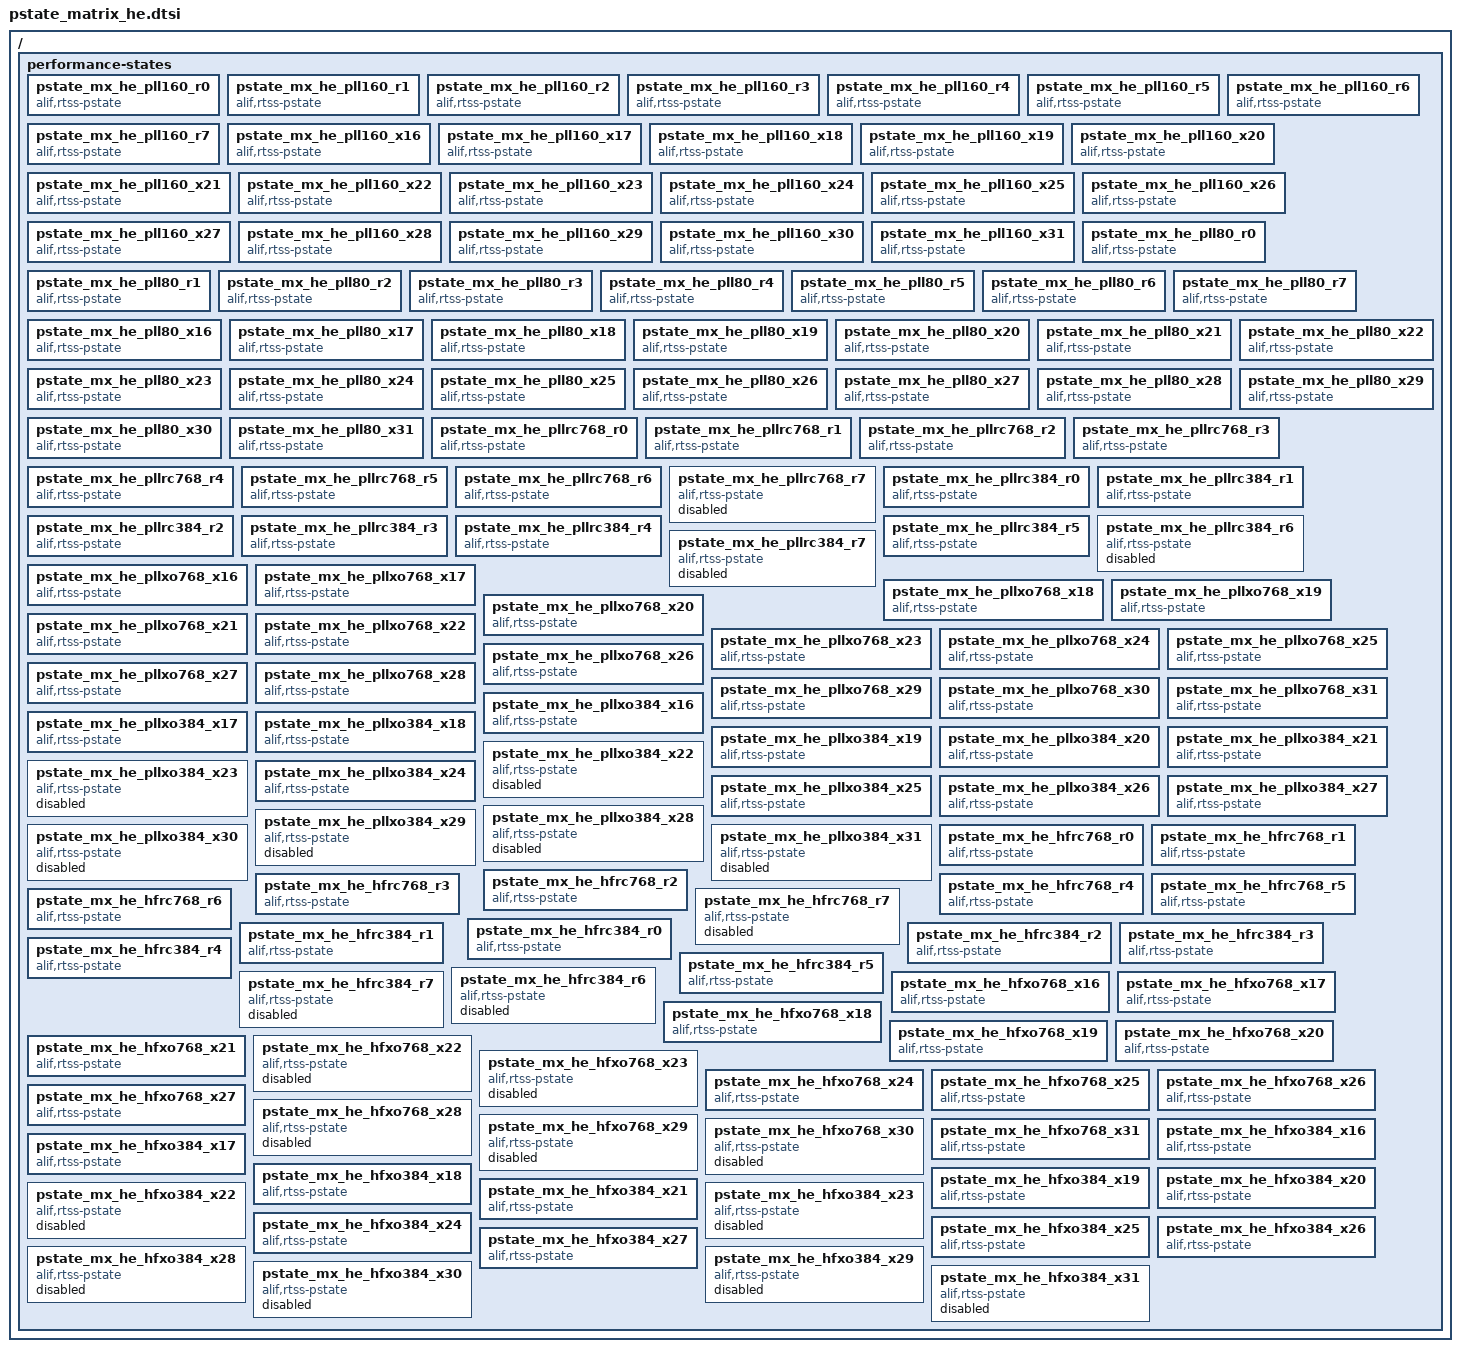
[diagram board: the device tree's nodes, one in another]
/* SPDX-FileCopyrightText: Copyright Analog Devices, Inc. */
/* SPDX-License-Identifier: Apache-2.0 */
/* Generated by scripts/regen_pstate_matrix.py */
/* HE matrix for E7/E8 (also E3/E4): PLL 160 and 80 MHz,
 * PLL x HFRC/HFXO cpu-clk-freq, HFRC src, and HFXO src.
 * E1C/B1 use pstate_matrix_he_e1c_b1.dtsi (160/80/120/60 + osc).
 */
#include <dt-bindings/misc/alif_aipm_common.h>

/ {
	performance-states {
		pstate_mx_he_pll160_r0: pstate_mx_he_pll160_r0 {
			compatible = "alif,rtss-pstate";
			load-threshold = <0>;
			cpu-clk-freq = <ALIF_CLOCK_FREQ_160MHZ>;
			clk-src = "pll";
			scaled-clk-freq = <ALIF_SCALED_FREQ_RC_ACTIVE_76_8_MHZ>;
			status = "okay";
		};
		pstate_mx_he_pll160_r1: pstate_mx_he_pll160_r1 {
			compatible = "alif,rtss-pstate";
			load-threshold = <0>;
			cpu-clk-freq = <ALIF_CLOCK_FREQ_160MHZ>;
			clk-src = "pll";
			scaled-clk-freq = <ALIF_SCALED_FREQ_RC_ACTIVE_38_4_MHZ>;
			status = "okay";
		};
		pstate_mx_he_pll160_r2: pstate_mx_he_pll160_r2 {
			compatible = "alif,rtss-pstate";
			load-threshold = <0>;
			cpu-clk-freq = <ALIF_CLOCK_FREQ_160MHZ>;
			clk-src = "pll";
			scaled-clk-freq = <ALIF_SCALED_FREQ_RC_ACTIVE_19_2_MHZ>;
			status = "okay";
		};
		pstate_mx_he_pll160_r3: pstate_mx_he_pll160_r3 {
			compatible = "alif,rtss-pstate";
			load-threshold = <0>;
			cpu-clk-freq = <ALIF_CLOCK_FREQ_160MHZ>;
			clk-src = "pll";
			scaled-clk-freq = <ALIF_SCALED_FREQ_RC_ACTIVE_9_6_MHZ>;
			status = "okay";
		};
		pstate_mx_he_pll160_r4: pstate_mx_he_pll160_r4 {
			compatible = "alif,rtss-pstate";
			load-threshold = <0>;
			cpu-clk-freq = <ALIF_CLOCK_FREQ_160MHZ>;
			clk-src = "pll";
			scaled-clk-freq = <ALIF_SCALED_FREQ_RC_ACTIVE_4_8_MHZ>;
			status = "okay";
		};
		pstate_mx_he_pll160_r5: pstate_mx_he_pll160_r5 {
			compatible = "alif,rtss-pstate";
			load-threshold = <0>;
			cpu-clk-freq = <ALIF_CLOCK_FREQ_160MHZ>;
			clk-src = "pll";
			scaled-clk-freq = <ALIF_SCALED_FREQ_RC_ACTIVE_2_4_MHZ>;
			status = "okay";
		};
		pstate_mx_he_pll160_r6: pstate_mx_he_pll160_r6 {
			compatible = "alif,rtss-pstate";
			load-threshold = <0>;
			cpu-clk-freq = <ALIF_CLOCK_FREQ_160MHZ>;
			clk-src = "pll";
			scaled-clk-freq = <ALIF_SCALED_FREQ_RC_ACTIVE_1_2_MHZ>;
			status = "okay";
		};
		pstate_mx_he_pll160_r7: pstate_mx_he_pll160_r7 {
			compatible = "alif,rtss-pstate";
			load-threshold = <0>;
			cpu-clk-freq = <ALIF_CLOCK_FREQ_160MHZ>;
			clk-src = "pll";
			scaled-clk-freq = <ALIF_SCALED_FREQ_RC_ACTIVE_0_6_MHZ>;
			status = "okay";
		};
		pstate_mx_he_pll160_x16: pstate_mx_he_pll160_x16 {
			compatible = "alif,rtss-pstate";
			load-threshold = <0>;
			cpu-clk-freq = <ALIF_CLOCK_FREQ_160MHZ>;
			clk-src = "pll";
			scaled-clk-freq = <ALIF_SCALED_FREQ_XO_LOW_DIV_38_4_MHZ>;
			status = "okay";
		};
		pstate_mx_he_pll160_x17: pstate_mx_he_pll160_x17 {
			compatible = "alif,rtss-pstate";
			load-threshold = <0>;
			cpu-clk-freq = <ALIF_CLOCK_FREQ_160MHZ>;
			clk-src = "pll";
			scaled-clk-freq = <ALIF_SCALED_FREQ_XO_LOW_DIV_19_2_MHZ>;
			status = "okay";
		};
		pstate_mx_he_pll160_x18: pstate_mx_he_pll160_x18 {
			compatible = "alif,rtss-pstate";
			load-threshold = <0>;
			cpu-clk-freq = <ALIF_CLOCK_FREQ_160MHZ>;
			clk-src = "pll";
			scaled-clk-freq = <ALIF_SCALED_FREQ_XO_LOW_DIV_9_6_MHZ>;
			status = "okay";
		};
		pstate_mx_he_pll160_x19: pstate_mx_he_pll160_x19 {
			compatible = "alif,rtss-pstate";
			load-threshold = <0>;
			cpu-clk-freq = <ALIF_CLOCK_FREQ_160MHZ>;
			clk-src = "pll";
			scaled-clk-freq = <ALIF_SCALED_FREQ_XO_LOW_DIV_4_8_MHZ>;
			status = "okay";
		};
		pstate_mx_he_pll160_x20: pstate_mx_he_pll160_x20 {
			compatible = "alif,rtss-pstate";
			load-threshold = <0>;
			cpu-clk-freq = <ALIF_CLOCK_FREQ_160MHZ>;
			clk-src = "pll";
			scaled-clk-freq = <ALIF_SCALED_FREQ_XO_LOW_DIV_2_4_MHZ>;
			status = "okay";
		};
		pstate_mx_he_pll160_x21: pstate_mx_he_pll160_x21 {
			compatible = "alif,rtss-pstate";
			load-threshold = <0>;
			cpu-clk-freq = <ALIF_CLOCK_FREQ_160MHZ>;
			clk-src = "pll";
			scaled-clk-freq = <ALIF_SCALED_FREQ_XO_LOW_DIV_1_2_MHZ>;
			status = "okay";
		};
		pstate_mx_he_pll160_x22: pstate_mx_he_pll160_x22 {
			compatible = "alif,rtss-pstate";
			load-threshold = <0>;
			cpu-clk-freq = <ALIF_CLOCK_FREQ_160MHZ>;
			clk-src = "pll";
			scaled-clk-freq = <ALIF_SCALED_FREQ_XO_LOW_DIV_0_6_MHZ>;
			status = "okay";
		};
		pstate_mx_he_pll160_x23: pstate_mx_he_pll160_x23 {
			compatible = "alif,rtss-pstate";
			load-threshold = <0>;
			cpu-clk-freq = <ALIF_CLOCK_FREQ_160MHZ>;
			clk-src = "pll";
			scaled-clk-freq = <ALIF_SCALED_FREQ_XO_LOW_DIV_0_3_MHZ>;
			status = "okay";
		};
		pstate_mx_he_pll160_x24: pstate_mx_he_pll160_x24 {
			compatible = "alif,rtss-pstate";
			load-threshold = <0>;
			cpu-clk-freq = <ALIF_CLOCK_FREQ_160MHZ>;
			clk-src = "pll";
			scaled-clk-freq = <ALIF_SCALED_FREQ_XO_HIGH_DIV_38_4_MHZ>;
			status = "okay";
		};
		pstate_mx_he_pll160_x25: pstate_mx_he_pll160_x25 {
			compatible = "alif,rtss-pstate";
			load-threshold = <0>;
			cpu-clk-freq = <ALIF_CLOCK_FREQ_160MHZ>;
			clk-src = "pll";
			scaled-clk-freq = <ALIF_SCALED_FREQ_XO_HIGH_DIV_19_2_MHZ>;
			status = "okay";
		};
		pstate_mx_he_pll160_x26: pstate_mx_he_pll160_x26 {
			compatible = "alif,rtss-pstate";
			load-threshold = <0>;
			cpu-clk-freq = <ALIF_CLOCK_FREQ_160MHZ>;
			clk-src = "pll";
			scaled-clk-freq = <ALIF_SCALED_FREQ_XO_HIGH_DIV_9_6_MHZ>;
			status = "okay";
		};
		pstate_mx_he_pll160_x27: pstate_mx_he_pll160_x27 {
			compatible = "alif,rtss-pstate";
			load-threshold = <0>;
			cpu-clk-freq = <ALIF_CLOCK_FREQ_160MHZ>;
			clk-src = "pll";
			scaled-clk-freq = <ALIF_SCALED_FREQ_XO_HIGH_DIV_2_4_MHZ>;
			status = "okay";
		};
		pstate_mx_he_pll160_x28: pstate_mx_he_pll160_x28 {
			compatible = "alif,rtss-pstate";
			load-threshold = <0>;
			cpu-clk-freq = <ALIF_CLOCK_FREQ_160MHZ>;
			clk-src = "pll";
			scaled-clk-freq = <ALIF_SCALED_FREQ_XO_HIGH_DIV_0_6_MHZ>;
			status = "okay";
		};
		pstate_mx_he_pll160_x29: pstate_mx_he_pll160_x29 {
			compatible = "alif,rtss-pstate";
			load-threshold = <0>;
			cpu-clk-freq = <ALIF_CLOCK_FREQ_160MHZ>;
			clk-src = "pll";
			scaled-clk-freq = <ALIF_SCALED_FREQ_XO_HIGH_DIV_0_3_MHZ>;
			status = "okay";
		};
		pstate_mx_he_pll160_x30: pstate_mx_he_pll160_x30 {
			compatible = "alif,rtss-pstate";
			load-threshold = <0>;
			cpu-clk-freq = <ALIF_CLOCK_FREQ_160MHZ>;
			clk-src = "pll";
			scaled-clk-freq = <ALIF_SCALED_FREQ_XO_HIGH_DIV_0_15_MHZ>;
			status = "okay";
		};
		pstate_mx_he_pll160_x31: pstate_mx_he_pll160_x31 {
			compatible = "alif,rtss-pstate";
			load-threshold = <0>;
			cpu-clk-freq = <ALIF_CLOCK_FREQ_160MHZ>;
			clk-src = "pll";
			scaled-clk-freq = <ALIF_SCALED_FREQ_XO_HIGH_DIV_0_0375_MHZ>;
			status = "okay";
		};
		pstate_mx_he_pll80_r0: pstate_mx_he_pll80_r0 {
			compatible = "alif,rtss-pstate";
			load-threshold = <0>;
			cpu-clk-freq = <ALIF_CLOCK_FREQ_80MHZ>;
			clk-src = "pll";
			scaled-clk-freq = <ALIF_SCALED_FREQ_RC_ACTIVE_76_8_MHZ>;
			status = "okay";
		};
		pstate_mx_he_pll80_r1: pstate_mx_he_pll80_r1 {
			compatible = "alif,rtss-pstate";
			load-threshold = <0>;
			cpu-clk-freq = <ALIF_CLOCK_FREQ_80MHZ>;
			clk-src = "pll";
			scaled-clk-freq = <ALIF_SCALED_FREQ_RC_ACTIVE_38_4_MHZ>;
			status = "okay";
		};
		pstate_mx_he_pll80_r2: pstate_mx_he_pll80_r2 {
			compatible = "alif,rtss-pstate";
			load-threshold = <0>;
			cpu-clk-freq = <ALIF_CLOCK_FREQ_80MHZ>;
			clk-src = "pll";
			scaled-clk-freq = <ALIF_SCALED_FREQ_RC_ACTIVE_19_2_MHZ>;
			status = "okay";
		};
		pstate_mx_he_pll80_r3: pstate_mx_he_pll80_r3 {
			compatible = "alif,rtss-pstate";
			load-threshold = <0>;
			cpu-clk-freq = <ALIF_CLOCK_FREQ_80MHZ>;
			clk-src = "pll";
			scaled-clk-freq = <ALIF_SCALED_FREQ_RC_ACTIVE_9_6_MHZ>;
			status = "okay";
		};
		pstate_mx_he_pll80_r4: pstate_mx_he_pll80_r4 {
			compatible = "alif,rtss-pstate";
			load-threshold = <0>;
			cpu-clk-freq = <ALIF_CLOCK_FREQ_80MHZ>;
			clk-src = "pll";
			scaled-clk-freq = <ALIF_SCALED_FREQ_RC_ACTIVE_4_8_MHZ>;
			status = "okay";
		};
		pstate_mx_he_pll80_r5: pstate_mx_he_pll80_r5 {
			compatible = "alif,rtss-pstate";
			load-threshold = <0>;
			cpu-clk-freq = <ALIF_CLOCK_FREQ_80MHZ>;
			clk-src = "pll";
			scaled-clk-freq = <ALIF_SCALED_FREQ_RC_ACTIVE_2_4_MHZ>;
			status = "okay";
		};
		pstate_mx_he_pll80_r6: pstate_mx_he_pll80_r6 {
			compatible = "alif,rtss-pstate";
			load-threshold = <0>;
			cpu-clk-freq = <ALIF_CLOCK_FREQ_80MHZ>;
			clk-src = "pll";
			scaled-clk-freq = <ALIF_SCALED_FREQ_RC_ACTIVE_1_2_MHZ>;
			status = "okay";
		};
		pstate_mx_he_pll80_r7: pstate_mx_he_pll80_r7 {
			compatible = "alif,rtss-pstate";
			load-threshold = <0>;
			cpu-clk-freq = <ALIF_CLOCK_FREQ_80MHZ>;
			clk-src = "pll";
			scaled-clk-freq = <ALIF_SCALED_FREQ_RC_ACTIVE_0_6_MHZ>;
			status = "okay";
		};
		pstate_mx_he_pll80_x16: pstate_mx_he_pll80_x16 {
			compatible = "alif,rtss-pstate";
			load-threshold = <0>;
			cpu-clk-freq = <ALIF_CLOCK_FREQ_80MHZ>;
			clk-src = "pll";
			scaled-clk-freq = <ALIF_SCALED_FREQ_XO_LOW_DIV_38_4_MHZ>;
			status = "okay";
		};
		pstate_mx_he_pll80_x17: pstate_mx_he_pll80_x17 {
			compatible = "alif,rtss-pstate";
			load-threshold = <0>;
			cpu-clk-freq = <ALIF_CLOCK_FREQ_80MHZ>;
			clk-src = "pll";
			scaled-clk-freq = <ALIF_SCALED_FREQ_XO_LOW_DIV_19_2_MHZ>;
			status = "okay";
		};
		pstate_mx_he_pll80_x18: pstate_mx_he_pll80_x18 {
			compatible = "alif,rtss-pstate";
			load-threshold = <0>;
			cpu-clk-freq = <ALIF_CLOCK_FREQ_80MHZ>;
			clk-src = "pll";
			scaled-clk-freq = <ALIF_SCALED_FREQ_XO_LOW_DIV_9_6_MHZ>;
			status = "okay";
		};
		pstate_mx_he_pll80_x19: pstate_mx_he_pll80_x19 {
			compatible = "alif,rtss-pstate";
			load-threshold = <0>;
			cpu-clk-freq = <ALIF_CLOCK_FREQ_80MHZ>;
			clk-src = "pll";
			scaled-clk-freq = <ALIF_SCALED_FREQ_XO_LOW_DIV_4_8_MHZ>;
			status = "okay";
		};
		pstate_mx_he_pll80_x20: pstate_mx_he_pll80_x20 {
			compatible = "alif,rtss-pstate";
			load-threshold = <0>;
			cpu-clk-freq = <ALIF_CLOCK_FREQ_80MHZ>;
			clk-src = "pll";
			scaled-clk-freq = <ALIF_SCALED_FREQ_XO_LOW_DIV_2_4_MHZ>;
			status = "okay";
		};
		pstate_mx_he_pll80_x21: pstate_mx_he_pll80_x21 {
			compatible = "alif,rtss-pstate";
			load-threshold = <0>;
			cpu-clk-freq = <ALIF_CLOCK_FREQ_80MHZ>;
			clk-src = "pll";
			scaled-clk-freq = <ALIF_SCALED_FREQ_XO_LOW_DIV_1_2_MHZ>;
			status = "okay";
		};
		pstate_mx_he_pll80_x22: pstate_mx_he_pll80_x22 {
			compatible = "alif,rtss-pstate";
			load-threshold = <0>;
			cpu-clk-freq = <ALIF_CLOCK_FREQ_80MHZ>;
			clk-src = "pll";
			scaled-clk-freq = <ALIF_SCALED_FREQ_XO_LOW_DIV_0_6_MHZ>;
			status = "okay";
		};
		pstate_mx_he_pll80_x23: pstate_mx_he_pll80_x23 {
			compatible = "alif,rtss-pstate";
			load-threshold = <0>;
			cpu-clk-freq = <ALIF_CLOCK_FREQ_80MHZ>;
			clk-src = "pll";
			scaled-clk-freq = <ALIF_SCALED_FREQ_XO_LOW_DIV_0_3_MHZ>;
			status = "okay";
		};
		pstate_mx_he_pll80_x24: pstate_mx_he_pll80_x24 {
			compatible = "alif,rtss-pstate";
			load-threshold = <0>;
			cpu-clk-freq = <ALIF_CLOCK_FREQ_80MHZ>;
			clk-src = "pll";
			scaled-clk-freq = <ALIF_SCALED_FREQ_XO_HIGH_DIV_38_4_MHZ>;
			status = "okay";
		};
		pstate_mx_he_pll80_x25: pstate_mx_he_pll80_x25 {
			compatible = "alif,rtss-pstate";
			load-threshold = <0>;
			cpu-clk-freq = <ALIF_CLOCK_FREQ_80MHZ>;
			clk-src = "pll";
			scaled-clk-freq = <ALIF_SCALED_FREQ_XO_HIGH_DIV_19_2_MHZ>;
			status = "okay";
		};
		pstate_mx_he_pll80_x26: pstate_mx_he_pll80_x26 {
			compatible = "alif,rtss-pstate";
			load-threshold = <0>;
			cpu-clk-freq = <ALIF_CLOCK_FREQ_80MHZ>;
			clk-src = "pll";
			scaled-clk-freq = <ALIF_SCALED_FREQ_XO_HIGH_DIV_9_6_MHZ>;
			status = "okay";
		};
		pstate_mx_he_pll80_x27: pstate_mx_he_pll80_x27 {
			compatible = "alif,rtss-pstate";
			load-threshold = <0>;
			cpu-clk-freq = <ALIF_CLOCK_FREQ_80MHZ>;
			clk-src = "pll";
			scaled-clk-freq = <ALIF_SCALED_FREQ_XO_HIGH_DIV_2_4_MHZ>;
			status = "okay";
		};
		pstate_mx_he_pll80_x28: pstate_mx_he_pll80_x28 {
			compatible = "alif,rtss-pstate";
			load-threshold = <0>;
			cpu-clk-freq = <ALIF_CLOCK_FREQ_80MHZ>;
			clk-src = "pll";
			scaled-clk-freq = <ALIF_SCALED_FREQ_XO_HIGH_DIV_0_6_MHZ>;
			status = "okay";
		};
		pstate_mx_he_pll80_x29: pstate_mx_he_pll80_x29 {
			compatible = "alif,rtss-pstate";
			load-threshold = <0>;
			cpu-clk-freq = <ALIF_CLOCK_FREQ_80MHZ>;
			clk-src = "pll";
			scaled-clk-freq = <ALIF_SCALED_FREQ_XO_HIGH_DIV_0_3_MHZ>;
			status = "okay";
		};
		pstate_mx_he_pll80_x30: pstate_mx_he_pll80_x30 {
			compatible = "alif,rtss-pstate";
			load-threshold = <0>;
			cpu-clk-freq = <ALIF_CLOCK_FREQ_80MHZ>;
			clk-src = "pll";
			scaled-clk-freq = <ALIF_SCALED_FREQ_XO_HIGH_DIV_0_15_MHZ>;
			status = "okay";
		};
		pstate_mx_he_pll80_x31: pstate_mx_he_pll80_x31 {
			compatible = "alif,rtss-pstate";
			load-threshold = <0>;
			cpu-clk-freq = <ALIF_CLOCK_FREQ_80MHZ>;
			clk-src = "pll";
			scaled-clk-freq = <ALIF_SCALED_FREQ_XO_HIGH_DIV_0_0375_MHZ>;
			status = "okay";
		};
		pstate_mx_he_pllrc768_r0: pstate_mx_he_pllrc768_r0 {
			compatible = "alif,rtss-pstate";
			load-threshold = <0>;
			cpu-clk-freq = <ALIF_CLOCK_FREQ_76_8_RC_MHZ>;
			clk-src = "pll";
			scaled-clk-freq = <ALIF_SCALED_FREQ_RC_ACTIVE_76_8_MHZ>;
			status = "okay";
		};
		pstate_mx_he_pllrc768_r1: pstate_mx_he_pllrc768_r1 {
			compatible = "alif,rtss-pstate";
			load-threshold = <0>;
			cpu-clk-freq = <ALIF_CLOCK_FREQ_76_8_RC_MHZ>;
			clk-src = "pll";
			scaled-clk-freq = <ALIF_SCALED_FREQ_RC_ACTIVE_38_4_MHZ>;
			status = "okay";
		};
		pstate_mx_he_pllrc768_r2: pstate_mx_he_pllrc768_r2 {
			compatible = "alif,rtss-pstate";
			load-threshold = <0>;
			cpu-clk-freq = <ALIF_CLOCK_FREQ_76_8_RC_MHZ>;
			clk-src = "pll";
			scaled-clk-freq = <ALIF_SCALED_FREQ_RC_ACTIVE_19_2_MHZ>;
			status = "okay";
		};
		pstate_mx_he_pllrc768_r3: pstate_mx_he_pllrc768_r3 {
			compatible = "alif,rtss-pstate";
			load-threshold = <0>;
			cpu-clk-freq = <ALIF_CLOCK_FREQ_76_8_RC_MHZ>;
			clk-src = "pll";
			scaled-clk-freq = <ALIF_SCALED_FREQ_RC_ACTIVE_9_6_MHZ>;
			status = "okay";
		};
		pstate_mx_he_pllrc768_r4: pstate_mx_he_pllrc768_r4 {
			compatible = "alif,rtss-pstate";
			load-threshold = <0>;
			cpu-clk-freq = <ALIF_CLOCK_FREQ_76_8_RC_MHZ>;
			clk-src = "pll";
			scaled-clk-freq = <ALIF_SCALED_FREQ_RC_ACTIVE_4_8_MHZ>;
			status = "okay";
		};
		pstate_mx_he_pllrc768_r5: pstate_mx_he_pllrc768_r5 {
			compatible = "alif,rtss-pstate";
			load-threshold = <0>;
			cpu-clk-freq = <ALIF_CLOCK_FREQ_76_8_RC_MHZ>;
			clk-src = "pll";
			scaled-clk-freq = <ALIF_SCALED_FREQ_RC_ACTIVE_2_4_MHZ>;
			status = "okay";
		};
		pstate_mx_he_pllrc768_r6: pstate_mx_he_pllrc768_r6 {
			compatible = "alif,rtss-pstate";
			load-threshold = <0>;
			cpu-clk-freq = <ALIF_CLOCK_FREQ_76_8_RC_MHZ>;
			clk-src = "pll";
			scaled-clk-freq = <ALIF_SCALED_FREQ_RC_ACTIVE_1_2_MHZ>;
			status = "okay";
		};
		/* Not in the default walk. Set status okay to verify this scaled frequency. */
		pstate_mx_he_pllrc768_r7: pstate_mx_he_pllrc768_r7 {
			compatible = "alif,rtss-pstate";
			load-threshold = <0>;
			cpu-clk-freq = <ALIF_CLOCK_FREQ_76_8_RC_MHZ>;
			clk-src = "pll";
			scaled-clk-freq = <ALIF_SCALED_FREQ_RC_ACTIVE_0_6_MHZ>;
			status = "disabled";
		};
		pstate_mx_he_pllrc384_r0: pstate_mx_he_pllrc384_r0 {
			compatible = "alif,rtss-pstate";
			load-threshold = <0>;
			cpu-clk-freq = <ALIF_CLOCK_FREQ_38_4_RC_MHZ>;
			clk-src = "pll";
			scaled-clk-freq = <ALIF_SCALED_FREQ_RC_ACTIVE_76_8_MHZ>;
			status = "okay";
		};
		pstate_mx_he_pllrc384_r1: pstate_mx_he_pllrc384_r1 {
			compatible = "alif,rtss-pstate";
			load-threshold = <0>;
			cpu-clk-freq = <ALIF_CLOCK_FREQ_38_4_RC_MHZ>;
			clk-src = "pll";
			scaled-clk-freq = <ALIF_SCALED_FREQ_RC_ACTIVE_38_4_MHZ>;
			status = "okay";
		};
		pstate_mx_he_pllrc384_r2: pstate_mx_he_pllrc384_r2 {
			compatible = "alif,rtss-pstate";
			load-threshold = <0>;
			cpu-clk-freq = <ALIF_CLOCK_FREQ_38_4_RC_MHZ>;
			clk-src = "pll";
			scaled-clk-freq = <ALIF_SCALED_FREQ_RC_ACTIVE_19_2_MHZ>;
			status = "okay";
		};
		pstate_mx_he_pllrc384_r3: pstate_mx_he_pllrc384_r3 {
			compatible = "alif,rtss-pstate";
			load-threshold = <0>;
			cpu-clk-freq = <ALIF_CLOCK_FREQ_38_4_RC_MHZ>;
			clk-src = "pll";
			scaled-clk-freq = <ALIF_SCALED_FREQ_RC_ACTIVE_9_6_MHZ>;
			status = "okay";
		};
		pstate_mx_he_pllrc384_r4: pstate_mx_he_pllrc384_r4 {
			compatible = "alif,rtss-pstate";
			load-threshold = <0>;
			cpu-clk-freq = <ALIF_CLOCK_FREQ_38_4_RC_MHZ>;
			clk-src = "pll";
			scaled-clk-freq = <ALIF_SCALED_FREQ_RC_ACTIVE_4_8_MHZ>;
			status = "okay";
		};
		pstate_mx_he_pllrc384_r5: pstate_mx_he_pllrc384_r5 {
			compatible = "alif,rtss-pstate";
			load-threshold = <0>;
			cpu-clk-freq = <ALIF_CLOCK_FREQ_38_4_RC_MHZ>;
			clk-src = "pll";
			scaled-clk-freq = <ALIF_SCALED_FREQ_RC_ACTIVE_2_4_MHZ>;
			status = "okay";
		};

		/* Not in the default walk. Set status okay to verify this scaled frequency. */
		pstate_mx_he_pllrc384_r6: pstate_mx_he_pllrc384_r6 {
			compatible = "alif,rtss-pstate";
			load-threshold = <0>;
			cpu-clk-freq = <ALIF_CLOCK_FREQ_38_4_RC_MHZ>;
			clk-src = "pll";
			scaled-clk-freq = <ALIF_SCALED_FREQ_RC_ACTIVE_1_2_MHZ>;
			status = "disabled";
		};

		/* Not in the default walk. Set status okay to verify this scaled frequency. */
		pstate_mx_he_pllrc384_r7: pstate_mx_he_pllrc384_r7 {
			compatible = "alif,rtss-pstate";
			load-threshold = <0>;
			cpu-clk-freq = <ALIF_CLOCK_FREQ_38_4_RC_MHZ>;
			clk-src = "pll";
			scaled-clk-freq = <ALIF_SCALED_FREQ_RC_ACTIVE_0_6_MHZ>;
			status = "disabled";
		};
		pstate_mx_he_pllxo768_x16: pstate_mx_he_pllxo768_x16 {
			compatible = "alif,rtss-pstate";
			load-threshold = <0>;
			cpu-clk-freq = <ALIF_CLOCK_FREQ_76_8_XO_MHZ>;
			clk-src = "pll";
			scaled-clk-freq = <ALIF_SCALED_FREQ_XO_LOW_DIV_38_4_MHZ>;
			status = "okay";
		};
		pstate_mx_he_pllxo768_x17: pstate_mx_he_pllxo768_x17 {
			compatible = "alif,rtss-pstate";
			load-threshold = <0>;
			cpu-clk-freq = <ALIF_CLOCK_FREQ_76_8_XO_MHZ>;
			clk-src = "pll";
			scaled-clk-freq = <ALIF_SCALED_FREQ_XO_LOW_DIV_19_2_MHZ>;
			status = "okay";
		};
		pstate_mx_he_pllxo768_x18: pstate_mx_he_pllxo768_x18 {
			compatible = "alif,rtss-pstate";
			load-threshold = <0>;
			cpu-clk-freq = <ALIF_CLOCK_FREQ_76_8_XO_MHZ>;
			clk-src = "pll";
			scaled-clk-freq = <ALIF_SCALED_FREQ_XO_LOW_DIV_9_6_MHZ>;
			status = "okay";
		};
		pstate_mx_he_pllxo768_x19: pstate_mx_he_pllxo768_x19 {
			compatible = "alif,rtss-pstate";
			load-threshold = <0>;
			cpu-clk-freq = <ALIF_CLOCK_FREQ_76_8_XO_MHZ>;
			clk-src = "pll";
			scaled-clk-freq = <ALIF_SCALED_FREQ_XO_LOW_DIV_4_8_MHZ>;
			status = "okay";
		};
		pstate_mx_he_pllxo768_x20: pstate_mx_he_pllxo768_x20 {
			compatible = "alif,rtss-pstate";
			load-threshold = <0>;
			cpu-clk-freq = <ALIF_CLOCK_FREQ_76_8_XO_MHZ>;
			clk-src = "pll";
			scaled-clk-freq = <ALIF_SCALED_FREQ_XO_LOW_DIV_2_4_MHZ>;
			status = "okay";
		};
		pstate_mx_he_pllxo768_x21: pstate_mx_he_pllxo768_x21 {
			compatible = "alif,rtss-pstate";
			load-threshold = <0>;
			cpu-clk-freq = <ALIF_CLOCK_FREQ_76_8_XO_MHZ>;
			clk-src = "pll";
			scaled-clk-freq = <ALIF_SCALED_FREQ_XO_LOW_DIV_1_2_MHZ>;
			status = "okay";
		};
		pstate_mx_he_pllxo768_x22: pstate_mx_he_pllxo768_x22 {
			compatible = "alif,rtss-pstate";
			load-threshold = <0>;
			cpu-clk-freq = <ALIF_CLOCK_FREQ_76_8_XO_MHZ>;
			clk-src = "pll";
			scaled-clk-freq = <ALIF_SCALED_FREQ_XO_LOW_DIV_0_6_MHZ>;
			status = "okay";
		};
		pstate_mx_he_pllxo768_x23: pstate_mx_he_pllxo768_x23 {
			compatible = "alif,rtss-pstate";
			load-threshold = <0>;
			cpu-clk-freq = <ALIF_CLOCK_FREQ_76_8_XO_MHZ>;
			clk-src = "pll";
			scaled-clk-freq = <ALIF_SCALED_FREQ_XO_LOW_DIV_0_3_MHZ>;
			status = "okay";
		};
		pstate_mx_he_pllxo768_x24: pstate_mx_he_pllxo768_x24 {
			compatible = "alif,rtss-pstate";
			load-threshold = <0>;
			cpu-clk-freq = <ALIF_CLOCK_FREQ_76_8_XO_MHZ>;
			clk-src = "pll";
			scaled-clk-freq = <ALIF_SCALED_FREQ_XO_HIGH_DIV_38_4_MHZ>;
			status = "okay";
		};
		pstate_mx_he_pllxo768_x25: pstate_mx_he_pllxo768_x25 {
			compatible = "alif,rtss-pstate";
			load-threshold = <0>;
			cpu-clk-freq = <ALIF_CLOCK_FREQ_76_8_XO_MHZ>;
			clk-src = "pll";
			scaled-clk-freq = <ALIF_SCALED_FREQ_XO_HIGH_DIV_19_2_MHZ>;
			status = "okay";
		};
		pstate_mx_he_pllxo768_x26: pstate_mx_he_pllxo768_x26 {
			compatible = "alif,rtss-pstate";
			load-threshold = <0>;
			cpu-clk-freq = <ALIF_CLOCK_FREQ_76_8_XO_MHZ>;
			clk-src = "pll";
			scaled-clk-freq = <ALIF_SCALED_FREQ_XO_HIGH_DIV_9_6_MHZ>;
			status = "okay";
		};
		pstate_mx_he_pllxo768_x27: pstate_mx_he_pllxo768_x27 {
			compatible = "alif,rtss-pstate";
			load-threshold = <0>;
			cpu-clk-freq = <ALIF_CLOCK_FREQ_76_8_XO_MHZ>;
			clk-src = "pll";
			scaled-clk-freq = <ALIF_SCALED_FREQ_XO_HIGH_DIV_2_4_MHZ>;
			status = "okay";
		};
		pstate_mx_he_pllxo768_x28: pstate_mx_he_pllxo768_x28 {
			compatible = "alif,rtss-pstate";
			load-threshold = <0>;
			cpu-clk-freq = <ALIF_CLOCK_FREQ_76_8_XO_MHZ>;
			clk-src = "pll";
			scaled-clk-freq = <ALIF_SCALED_FREQ_XO_HIGH_DIV_0_6_MHZ>;
			status = "okay";
		};
		pstate_mx_he_pllxo768_x29: pstate_mx_he_pllxo768_x29 {
			compatible = "alif,rtss-pstate";
			load-threshold = <0>;
			cpu-clk-freq = <ALIF_CLOCK_FREQ_76_8_XO_MHZ>;
			clk-src = "pll";
			scaled-clk-freq = <ALIF_SCALED_FREQ_XO_HIGH_DIV_0_3_MHZ>;
			status = "okay";
		};
		pstate_mx_he_pllxo768_x30: pstate_mx_he_pllxo768_x30 {
			compatible = "alif,rtss-pstate";
			load-threshold = <0>;
			cpu-clk-freq = <ALIF_CLOCK_FREQ_76_8_XO_MHZ>;
			clk-src = "pll";
			scaled-clk-freq = <ALIF_SCALED_FREQ_XO_HIGH_DIV_0_15_MHZ>;
			status = "okay";
		};
		pstate_mx_he_pllxo768_x31: pstate_mx_he_pllxo768_x31 {
			compatible = "alif,rtss-pstate";
			load-threshold = <0>;
			cpu-clk-freq = <ALIF_CLOCK_FREQ_76_8_XO_MHZ>;
			clk-src = "pll";
			scaled-clk-freq = <ALIF_SCALED_FREQ_XO_HIGH_DIV_0_0375_MHZ>;
			status = "okay";
		};
		pstate_mx_he_pllxo384_x16: pstate_mx_he_pllxo384_x16 {
			compatible = "alif,rtss-pstate";
			load-threshold = <0>;
			cpu-clk-freq = <ALIF_CLOCK_FREQ_38_4_XO_MHZ>;
			clk-src = "pll";
			scaled-clk-freq = <ALIF_SCALED_FREQ_XO_LOW_DIV_38_4_MHZ>;
			status = "okay";
		};
		pstate_mx_he_pllxo384_x17: pstate_mx_he_pllxo384_x17 {
			compatible = "alif,rtss-pstate";
			load-threshold = <0>;
			cpu-clk-freq = <ALIF_CLOCK_FREQ_38_4_XO_MHZ>;
			clk-src = "pll";
			scaled-clk-freq = <ALIF_SCALED_FREQ_XO_LOW_DIV_19_2_MHZ>;
			status = "okay";
		};
		pstate_mx_he_pllxo384_x18: pstate_mx_he_pllxo384_x18 {
			compatible = "alif,rtss-pstate";
			load-threshold = <0>;
			cpu-clk-freq = <ALIF_CLOCK_FREQ_38_4_XO_MHZ>;
			clk-src = "pll";
			scaled-clk-freq = <ALIF_SCALED_FREQ_XO_LOW_DIV_9_6_MHZ>;
			status = "okay";
		};
		pstate_mx_he_pllxo384_x19: pstate_mx_he_pllxo384_x19 {
			compatible = "alif,rtss-pstate";
			load-threshold = <0>;
			cpu-clk-freq = <ALIF_CLOCK_FREQ_38_4_XO_MHZ>;
			clk-src = "pll";
			scaled-clk-freq = <ALIF_SCALED_FREQ_XO_LOW_DIV_4_8_MHZ>;
			status = "okay";
		};
		pstate_mx_he_pllxo384_x20: pstate_mx_he_pllxo384_x20 {
			compatible = "alif,rtss-pstate";
			load-threshold = <0>;
			cpu-clk-freq = <ALIF_CLOCK_FREQ_38_4_XO_MHZ>;
			clk-src = "pll";
			scaled-clk-freq = <ALIF_SCALED_FREQ_XO_LOW_DIV_2_4_MHZ>;
			status = "okay";
		};
		pstate_mx_he_pllxo384_x21: pstate_mx_he_pllxo384_x21 {
			compatible = "alif,rtss-pstate";
			load-threshold = <0>;
			cpu-clk-freq = <ALIF_CLOCK_FREQ_38_4_XO_MHZ>;
			clk-src = "pll";
			scaled-clk-freq = <ALIF_SCALED_FREQ_XO_LOW_DIV_1_2_MHZ>;
			status = "okay";
		};
		/* Not in the default walk. Set status okay to verify this scaled frequency. */
		pstate_mx_he_pllxo384_x22: pstate_mx_he_pllxo384_x22 {
			compatible = "alif,rtss-pstate";
			load-threshold = <0>;
			cpu-clk-freq = <ALIF_CLOCK_FREQ_38_4_XO_MHZ>;
			clk-src = "pll";
			scaled-clk-freq = <ALIF_SCALED_FREQ_XO_LOW_DIV_0_6_MHZ>;
			status = "disabled";
		};
		/* Not in the default walk. Set status okay to verify this scaled frequency. */
		pstate_mx_he_pllxo384_x23: pstate_mx_he_pllxo384_x23 {
			compatible = "alif,rtss-pstate";
			load-threshold = <0>;
			cpu-clk-freq = <ALIF_CLOCK_FREQ_38_4_XO_MHZ>;
			clk-src = "pll";
			scaled-clk-freq = <ALIF_SCALED_FREQ_XO_LOW_DIV_0_3_MHZ>;
			status = "disabled";
		};
		pstate_mx_he_pllxo384_x24: pstate_mx_he_pllxo384_x24 {
			compatible = "alif,rtss-pstate";
			load-threshold = <0>;
			cpu-clk-freq = <ALIF_CLOCK_FREQ_38_4_XO_MHZ>;
			clk-src = "pll";
			scaled-clk-freq = <ALIF_SCALED_FREQ_XO_HIGH_DIV_38_4_MHZ>;
			status = "okay";
		};
		pstate_mx_he_pllxo384_x25: pstate_mx_he_pllxo384_x25 {
			compatible = "alif,rtss-pstate";
			load-threshold = <0>;
			cpu-clk-freq = <ALIF_CLOCK_FREQ_38_4_XO_MHZ>;
			clk-src = "pll";
			scaled-clk-freq = <ALIF_SCALED_FREQ_XO_HIGH_DIV_19_2_MHZ>;
			status = "okay";
		};
		pstate_mx_he_pllxo384_x26: pstate_mx_he_pllxo384_x26 {
			compatible = "alif,rtss-pstate";
			load-threshold = <0>;
			cpu-clk-freq = <ALIF_CLOCK_FREQ_38_4_XO_MHZ>;
			clk-src = "pll";
			scaled-clk-freq = <ALIF_SCALED_FREQ_XO_HIGH_DIV_9_6_MHZ>;
			status = "okay";
		};
		pstate_mx_he_pllxo384_x27: pstate_mx_he_pllxo384_x27 {
			compatible = "alif,rtss-pstate";
			load-threshold = <0>;
			cpu-clk-freq = <ALIF_CLOCK_FREQ_38_4_XO_MHZ>;
			clk-src = "pll";
			scaled-clk-freq = <ALIF_SCALED_FREQ_XO_HIGH_DIV_2_4_MHZ>;
			status = "okay";
		};
		/* Not in the default walk. Set status okay to verify this scaled frequency. */
		pstate_mx_he_pllxo384_x28: pstate_mx_he_pllxo384_x28 {
			compatible = "alif,rtss-pstate";
			load-threshold = <0>;
			cpu-clk-freq = <ALIF_CLOCK_FREQ_38_4_XO_MHZ>;
			clk-src = "pll";
			scaled-clk-freq = <ALIF_SCALED_FREQ_XO_HIGH_DIV_0_6_MHZ>;
			status = "disabled";
		};
		/* Not in the default walk. Set status okay to verify this scaled frequency. */
		pstate_mx_he_pllxo384_x29: pstate_mx_he_pllxo384_x29 {
			compatible = "alif,rtss-pstate";
			load-threshold = <0>;
			cpu-clk-freq = <ALIF_CLOCK_FREQ_38_4_XO_MHZ>;
			clk-src = "pll";
			scaled-clk-freq = <ALIF_SCALED_FREQ_XO_HIGH_DIV_0_3_MHZ>;
			status = "disabled";
		};
		/* Not in the default walk. Set status okay to verify this scaled frequency. */
		pstate_mx_he_pllxo384_x30: pstate_mx_he_pllxo384_x30 {
			compatible = "alif,rtss-pstate";
			load-threshold = <0>;
			cpu-clk-freq = <ALIF_CLOCK_FREQ_38_4_XO_MHZ>;
			clk-src = "pll";
			scaled-clk-freq = <ALIF_SCALED_FREQ_XO_HIGH_DIV_0_15_MHZ>;
			status = "disabled";
		};
		/* Not in the default walk. Set status okay to verify this scaled frequency. */
		pstate_mx_he_pllxo384_x31: pstate_mx_he_pllxo384_x31 {
			compatible = "alif,rtss-pstate";
			load-threshold = <0>;
			cpu-clk-freq = <ALIF_CLOCK_FREQ_38_4_XO_MHZ>;
			clk-src = "pll";
			scaled-clk-freq = <ALIF_SCALED_FREQ_XO_HIGH_DIV_0_0375_MHZ>;
			status = "disabled";
		};
		pstate_mx_he_hfrc768_r0: pstate_mx_he_hfrc768_r0 {
			compatible = "alif,rtss-pstate";
			load-threshold = <0>;
			cpu-clk-freq = <ALIF_CLOCK_FREQ_76_8_RC_MHZ>;
			clk-src = "hfrc";
			scaled-clk-freq = <ALIF_SCALED_FREQ_RC_ACTIVE_76_8_MHZ>;
			status = "okay";
		};
		pstate_mx_he_hfrc768_r1: pstate_mx_he_hfrc768_r1 {
			compatible = "alif,rtss-pstate";
			load-threshold = <0>;
			cpu-clk-freq = <ALIF_CLOCK_FREQ_76_8_RC_MHZ>;
			clk-src = "hfrc";
			scaled-clk-freq = <ALIF_SCALED_FREQ_RC_ACTIVE_38_4_MHZ>;
			status = "okay";
		};
		pstate_mx_he_hfrc768_r2: pstate_mx_he_hfrc768_r2 {
			compatible = "alif,rtss-pstate";
			load-threshold = <0>;
			cpu-clk-freq = <ALIF_CLOCK_FREQ_76_8_RC_MHZ>;
			clk-src = "hfrc";
			scaled-clk-freq = <ALIF_SCALED_FREQ_RC_ACTIVE_19_2_MHZ>;
			status = "okay";
		};
		pstate_mx_he_hfrc768_r3: pstate_mx_he_hfrc768_r3 {
			compatible = "alif,rtss-pstate";
			load-threshold = <0>;
			cpu-clk-freq = <ALIF_CLOCK_FREQ_76_8_RC_MHZ>;
			clk-src = "hfrc";
			scaled-clk-freq = <ALIF_SCALED_FREQ_RC_ACTIVE_9_6_MHZ>;
			status = "okay";
		};
		pstate_mx_he_hfrc768_r4: pstate_mx_he_hfrc768_r4 {
			compatible = "alif,rtss-pstate";
			load-threshold = <0>;
			cpu-clk-freq = <ALIF_CLOCK_FREQ_76_8_RC_MHZ>;
			clk-src = "hfrc";
			scaled-clk-freq = <ALIF_SCALED_FREQ_RC_ACTIVE_4_8_MHZ>;
			status = "okay";
		};
		pstate_mx_he_hfrc768_r5: pstate_mx_he_hfrc768_r5 {
			compatible = "alif,rtss-pstate";
			load-threshold = <0>;
			cpu-clk-freq = <ALIF_CLOCK_FREQ_76_8_RC_MHZ>;
			clk-src = "hfrc";
			scaled-clk-freq = <ALIF_SCALED_FREQ_RC_ACTIVE_2_4_MHZ>;
			status = "okay";
		};
		pstate_mx_he_hfrc768_r6: pstate_mx_he_hfrc768_r6 {
			compatible = "alif,rtss-pstate";
			load-threshold = <0>;
			cpu-clk-freq = <ALIF_CLOCK_FREQ_76_8_RC_MHZ>;
			clk-src = "hfrc";
			scaled-clk-freq = <ALIF_SCALED_FREQ_RC_ACTIVE_1_2_MHZ>;
			status = "okay";
		};
		/* Not in the default walk. Set status okay to verify this scaled frequency. */
		pstate_mx_he_hfrc768_r7: pstate_mx_he_hfrc768_r7 {
			compatible = "alif,rtss-pstate";
			load-threshold = <0>;
			cpu-clk-freq = <ALIF_CLOCK_FREQ_76_8_RC_MHZ>;
			clk-src = "hfrc";
			scaled-clk-freq = <ALIF_SCALED_FREQ_RC_ACTIVE_0_6_MHZ>;
			status = "disabled";
		};
		pstate_mx_he_hfrc384_r0: pstate_mx_he_hfrc384_r0 {
			compatible = "alif,rtss-pstate";
			load-threshold = <0>;
			cpu-clk-freq = <ALIF_CLOCK_FREQ_38_4_RC_MHZ>;
			clk-src = "hfrc";
			scaled-clk-freq = <ALIF_SCALED_FREQ_RC_ACTIVE_76_8_MHZ>;
			status = "okay";
		};
		pstate_mx_he_hfrc384_r1: pstate_mx_he_hfrc384_r1 {
			compatible = "alif,rtss-pstate";
			load-threshold = <0>;
			cpu-clk-freq = <ALIF_CLOCK_FREQ_38_4_RC_MHZ>;
			clk-src = "hfrc";
			scaled-clk-freq = <ALIF_SCALED_FREQ_RC_ACTIVE_38_4_MHZ>;
			status = "okay";
		};
		pstate_mx_he_hfrc384_r2: pstate_mx_he_hfrc384_r2 {
			compatible = "alif,rtss-pstate";
			load-threshold = <0>;
			cpu-clk-freq = <ALIF_CLOCK_FREQ_38_4_RC_MHZ>;
			clk-src = "hfrc";
			scaled-clk-freq = <ALIF_SCALED_FREQ_RC_ACTIVE_19_2_MHZ>;
			status = "okay";
		};
		pstate_mx_he_hfrc384_r3: pstate_mx_he_hfrc384_r3 {
			compatible = "alif,rtss-pstate";
			load-threshold = <0>;
			cpu-clk-freq = <ALIF_CLOCK_FREQ_38_4_RC_MHZ>;
			clk-src = "hfrc";
			scaled-clk-freq = <ALIF_SCALED_FREQ_RC_ACTIVE_9_6_MHZ>;
			status = "okay";
		};
		pstate_mx_he_hfrc384_r4: pstate_mx_he_hfrc384_r4 {
			compatible = "alif,rtss-pstate";
			load-threshold = <0>;
			cpu-clk-freq = <ALIF_CLOCK_FREQ_38_4_RC_MHZ>;
			clk-src = "hfrc";
			scaled-clk-freq = <ALIF_SCALED_FREQ_RC_ACTIVE_4_8_MHZ>;
			status = "okay";
		};
		pstate_mx_he_hfrc384_r5: pstate_mx_he_hfrc384_r5 {
			compatible = "alif,rtss-pstate";
			load-threshold = <0>;
			cpu-clk-freq = <ALIF_CLOCK_FREQ_38_4_RC_MHZ>;
			clk-src = "hfrc";
			scaled-clk-freq = <ALIF_SCALED_FREQ_RC_ACTIVE_2_4_MHZ>;
			status = "okay";
		};
		/* Not in the default walk. Set status okay to verify this scaled frequency. */
		pstate_mx_he_hfrc384_r6: pstate_mx_he_hfrc384_r6 {
			compatible = "alif,rtss-pstate";
			load-threshold = <0>;
			cpu-clk-freq = <ALIF_CLOCK_FREQ_38_4_RC_MHZ>;
			clk-src = "hfrc";
			scaled-clk-freq = <ALIF_SCALED_FREQ_RC_ACTIVE_1_2_MHZ>;
			status = "disabled";
		};
		/* Not in the default walk. Set status okay to verify this scaled frequency. */
		pstate_mx_he_hfrc384_r7: pstate_mx_he_hfrc384_r7 {
			compatible = "alif,rtss-pstate";
			load-threshold = <0>;
			cpu-clk-freq = <ALIF_CLOCK_FREQ_38_4_RC_MHZ>;
			clk-src = "hfrc";
			scaled-clk-freq = <ALIF_SCALED_FREQ_RC_ACTIVE_0_6_MHZ>;
			status = "disabled";
		};
		pstate_mx_he_hfxo768_x16: pstate_mx_he_hfxo768_x16 {
			compatible = "alif,rtss-pstate";
			load-threshold = <0>;
			cpu-clk-freq = <ALIF_CLOCK_FREQ_76_8_XO_MHZ>;
			clk-src = "hfxo";
			scaled-clk-freq = <ALIF_SCALED_FREQ_XO_LOW_DIV_38_4_MHZ>;
			status = "okay";
		};
		pstate_mx_he_hfxo768_x17: pstate_mx_he_hfxo768_x17 {
			compatible = "alif,rtss-pstate";
			load-threshold = <0>;
			cpu-clk-freq = <ALIF_CLOCK_FREQ_76_8_XO_MHZ>;
			clk-src = "hfxo";
			scaled-clk-freq = <ALIF_SCALED_FREQ_XO_LOW_DIV_19_2_MHZ>;
			status = "okay";
		};
		pstate_mx_he_hfxo768_x18: pstate_mx_he_hfxo768_x18 {
			compatible = "alif,rtss-pstate";
			load-threshold = <0>;
			cpu-clk-freq = <ALIF_CLOCK_FREQ_76_8_XO_MHZ>;
			clk-src = "hfxo";
			scaled-clk-freq = <ALIF_SCALED_FREQ_XO_LOW_DIV_9_6_MHZ>;
			status = "okay";
		};
		pstate_mx_he_hfxo768_x19: pstate_mx_he_hfxo768_x19 {
			compatible = "alif,rtss-pstate";
			load-threshold = <0>;
			cpu-clk-freq = <ALIF_CLOCK_FREQ_76_8_XO_MHZ>;
			clk-src = "hfxo";
			scaled-clk-freq = <ALIF_SCALED_FREQ_XO_LOW_DIV_4_8_MHZ>;
			status = "okay";
		};
		pstate_mx_he_hfxo768_x20: pstate_mx_he_hfxo768_x20 {
			compatible = "alif,rtss-pstate";
			load-threshold = <0>;
			cpu-clk-freq = <ALIF_CLOCK_FREQ_76_8_XO_MHZ>;
			clk-src = "hfxo";
			scaled-clk-freq = <ALIF_SCALED_FREQ_XO_LOW_DIV_2_4_MHZ>;
			status = "okay";
		};
		pstate_mx_he_hfxo768_x21: pstate_mx_he_hfxo768_x21 {
			compatible = "alif,rtss-pstate";
			load-threshold = <0>;
			cpu-clk-freq = <ALIF_CLOCK_FREQ_76_8_XO_MHZ>;
			clk-src = "hfxo";
			scaled-clk-freq = <ALIF_SCALED_FREQ_XO_LOW_DIV_1_2_MHZ>;
			status = "okay";
		};
		/* Not in the default walk. Set status okay to verify this scaled frequency. */
		pstate_mx_he_hfxo768_x22: pstate_mx_he_hfxo768_x22 {
			compatible = "alif,rtss-pstate";
			load-threshold = <0>;
			cpu-clk-freq = <ALIF_CLOCK_FREQ_76_8_XO_MHZ>;
			clk-src = "hfxo";
			scaled-clk-freq = <ALIF_SCALED_FREQ_XO_LOW_DIV_0_6_MHZ>;
			status = "disabled";
		};
		/* Not in the default walk. Set status okay to verify this scaled frequency. */
		pstate_mx_he_hfxo768_x23: pstate_mx_he_hfxo768_x23 {
			compatible = "alif,rtss-pstate";
			load-threshold = <0>;
			cpu-clk-freq = <ALIF_CLOCK_FREQ_76_8_XO_MHZ>;
			clk-src = "hfxo";
			scaled-clk-freq = <ALIF_SCALED_FREQ_XO_LOW_DIV_0_3_MHZ>;
			status = "disabled";
		};
		pstate_mx_he_hfxo768_x24: pstate_mx_he_hfxo768_x24 {
			compatible = "alif,rtss-pstate";
			load-threshold = <0>;
			cpu-clk-freq = <ALIF_CLOCK_FREQ_76_8_XO_MHZ>;
			clk-src = "hfxo";
			scaled-clk-freq = <ALIF_SCALED_FREQ_XO_HIGH_DIV_38_4_MHZ>;
			status = "okay";
		};
		pstate_mx_he_hfxo768_x25: pstate_mx_he_hfxo768_x25 {
			compatible = "alif,rtss-pstate";
			load-threshold = <0>;
			cpu-clk-freq = <ALIF_CLOCK_FREQ_76_8_XO_MHZ>;
			clk-src = "hfxo";
			scaled-clk-freq = <ALIF_SCALED_FREQ_XO_HIGH_DIV_19_2_MHZ>;
			status = "okay";
		};
		pstate_mx_he_hfxo768_x26: pstate_mx_he_hfxo768_x26 {
			compatible = "alif,rtss-pstate";
			load-threshold = <0>;
			cpu-clk-freq = <ALIF_CLOCK_FREQ_76_8_XO_MHZ>;
			clk-src = "hfxo";
			scaled-clk-freq = <ALIF_SCALED_FREQ_XO_HIGH_DIV_9_6_MHZ>;
			status = "okay";
		};
		pstate_mx_he_hfxo768_x27: pstate_mx_he_hfxo768_x27 {
			compatible = "alif,rtss-pstate";
			load-threshold = <0>;
			cpu-clk-freq = <ALIF_CLOCK_FREQ_76_8_XO_MHZ>;
			clk-src = "hfxo";
			scaled-clk-freq = <ALIF_SCALED_FREQ_XO_HIGH_DIV_2_4_MHZ>;
			status = "okay";
		};
		/* Not in the default walk. Set status okay to verify this scaled frequency. */
		pstate_mx_he_hfxo768_x28: pstate_mx_he_hfxo768_x28 {
			compatible = "alif,rtss-pstate";
			load-threshold = <0>;
			cpu-clk-freq = <ALIF_CLOCK_FREQ_76_8_XO_MHZ>;
			clk-src = "hfxo";
			scaled-clk-freq = <ALIF_SCALED_FREQ_XO_HIGH_DIV_0_6_MHZ>;
			status = "disabled";
		};
		/* Not in the default walk. Set status okay to verify this scaled frequency. */
		pstate_mx_he_hfxo768_x29: pstate_mx_he_hfxo768_x29 {
			compatible = "alif,rtss-pstate";
			load-threshold = <0>;
			cpu-clk-freq = <ALIF_CLOCK_FREQ_76_8_XO_MHZ>;
			clk-src = "hfxo";
			scaled-clk-freq = <ALIF_SCALED_FREQ_XO_HIGH_DIV_0_3_MHZ>;
			status = "disabled";
		};
		/* Not in the default walk. Set status okay to verify this scaled frequency. */
		pstate_mx_he_hfxo768_x30: pstate_mx_he_hfxo768_x30 {
			compatible = "alif,rtss-pstate";
			load-threshold = <0>;
			cpu-clk-freq = <ALIF_CLOCK_FREQ_76_8_XO_MHZ>;
			clk-src = "hfxo";
			scaled-clk-freq = <ALIF_SCALED_FREQ_XO_HIGH_DIV_0_15_MHZ>;
			status = "disabled";
		};
		pstate_mx_he_hfxo768_x31: pstate_mx_he_hfxo768_x31 {
			compatible = "alif,rtss-pstate";
			load-threshold = <0>;
			cpu-clk-freq = <ALIF_CLOCK_FREQ_76_8_XO_MHZ>;
			clk-src = "hfxo";
			scaled-clk-freq = <ALIF_SCALED_FREQ_XO_HIGH_DIV_0_0375_MHZ>;
			status = "okay";
		};
		pstate_mx_he_hfxo384_x16: pstate_mx_he_hfxo384_x16 {
			compatible = "alif,rtss-pstate";
			load-threshold = <0>;
			cpu-clk-freq = <ALIF_CLOCK_FREQ_38_4_XO_MHZ>;
			clk-src = "hfxo";
			scaled-clk-freq = <ALIF_SCALED_FREQ_XO_LOW_DIV_38_4_MHZ>;
			status = "okay";
		};
		pstate_mx_he_hfxo384_x17: pstate_mx_he_hfxo384_x17 {
			compatible = "alif,rtss-pstate";
			load-threshold = <0>;
			cpu-clk-freq = <ALIF_CLOCK_FREQ_38_4_XO_MHZ>;
			clk-src = "hfxo";
			scaled-clk-freq = <ALIF_SCALED_FREQ_XO_LOW_DIV_19_2_MHZ>;
			status = "okay";
		};
		pstate_mx_he_hfxo384_x18: pstate_mx_he_hfxo384_x18 {
			compatible = "alif,rtss-pstate";
			load-threshold = <0>;
			cpu-clk-freq = <ALIF_CLOCK_FREQ_38_4_XO_MHZ>;
			clk-src = "hfxo";
			scaled-clk-freq = <ALIF_SCALED_FREQ_XO_LOW_DIV_9_6_MHZ>;
			status = "okay";
		};
		pstate_mx_he_hfxo384_x19: pstate_mx_he_hfxo384_x19 {
			compatible = "alif,rtss-pstate";
			load-threshold = <0>;
			cpu-clk-freq = <ALIF_CLOCK_FREQ_38_4_XO_MHZ>;
			clk-src = "hfxo";
			scaled-clk-freq = <ALIF_SCALED_FREQ_XO_LOW_DIV_4_8_MHZ>;
			status = "okay";
		};
		pstate_mx_he_hfxo384_x20: pstate_mx_he_hfxo384_x20 {
			compatible = "alif,rtss-pstate";
			load-threshold = <0>;
			cpu-clk-freq = <ALIF_CLOCK_FREQ_38_4_XO_MHZ>;
			clk-src = "hfxo";
			scaled-clk-freq = <ALIF_SCALED_FREQ_XO_LOW_DIV_2_4_MHZ>;
			status = "okay";
		};
		pstate_mx_he_hfxo384_x21: pstate_mx_he_hfxo384_x21 {
			compatible = "alif,rtss-pstate";
			load-threshold = <0>;
			cpu-clk-freq = <ALIF_CLOCK_FREQ_38_4_XO_MHZ>;
			clk-src = "hfxo";
			scaled-clk-freq = <ALIF_SCALED_FREQ_XO_LOW_DIV_1_2_MHZ>;
			status = "okay";
		};
		/* Not in the default walk. Set status okay to verify this scaled frequency. */
		pstate_mx_he_hfxo384_x22: pstate_mx_he_hfxo384_x22 {
			compatible = "alif,rtss-pstate";
			load-threshold = <0>;
			cpu-clk-freq = <ALIF_CLOCK_FREQ_38_4_XO_MHZ>;
			clk-src = "hfxo";
			scaled-clk-freq = <ALIF_SCALED_FREQ_XO_LOW_DIV_0_6_MHZ>;
			status = "disabled";
		};
		/* Not in the default walk. Set status okay to verify this scaled frequency. */
		pstate_mx_he_hfxo384_x23: pstate_mx_he_hfxo384_x23 {
			compatible = "alif,rtss-pstate";
			load-threshold = <0>;
			cpu-clk-freq = <ALIF_CLOCK_FREQ_38_4_XO_MHZ>;
			clk-src = "hfxo";
			scaled-clk-freq = <ALIF_SCALED_FREQ_XO_LOW_DIV_0_3_MHZ>;
			status = "disabled";
		};
		pstate_mx_he_hfxo384_x24: pstate_mx_he_hfxo384_x24 {
			compatible = "alif,rtss-pstate";
			load-threshold = <0>;
			cpu-clk-freq = <ALIF_CLOCK_FREQ_38_4_XO_MHZ>;
			clk-src = "hfxo";
			scaled-clk-freq = <ALIF_SCALED_FREQ_XO_HIGH_DIV_38_4_MHZ>;
			status = "okay";
		};
		pstate_mx_he_hfxo384_x25: pstate_mx_he_hfxo384_x25 {
			compatible = "alif,rtss-pstate";
			load-threshold = <0>;
			cpu-clk-freq = <ALIF_CLOCK_FREQ_38_4_XO_MHZ>;
			clk-src = "hfxo";
			scaled-clk-freq = <ALIF_SCALED_FREQ_XO_HIGH_DIV_19_2_MHZ>;
			status = "okay";
		};
		pstate_mx_he_hfxo384_x26: pstate_mx_he_hfxo384_x26 {
			compatible = "alif,rtss-pstate";
			load-threshold = <0>;
			cpu-clk-freq = <ALIF_CLOCK_FREQ_38_4_XO_MHZ>;
			clk-src = "hfxo";
			scaled-clk-freq = <ALIF_SCALED_FREQ_XO_HIGH_DIV_9_6_MHZ>;
			status = "okay";
		};
		pstate_mx_he_hfxo384_x27: pstate_mx_he_hfxo384_x27 {
			compatible = "alif,rtss-pstate";
			load-threshold = <0>;
			cpu-clk-freq = <ALIF_CLOCK_FREQ_38_4_XO_MHZ>;
			clk-src = "hfxo";
			scaled-clk-freq = <ALIF_SCALED_FREQ_XO_HIGH_DIV_2_4_MHZ>;
			status = "okay";
		};
		/* Not in the default walk. Set status okay to verify this scaled frequency. */
		pstate_mx_he_hfxo384_x28: pstate_mx_he_hfxo384_x28 {
			compatible = "alif,rtss-pstate";
			load-threshold = <0>;
			cpu-clk-freq = <ALIF_CLOCK_FREQ_38_4_XO_MHZ>;
			clk-src = "hfxo";
			scaled-clk-freq = <ALIF_SCALED_FREQ_XO_HIGH_DIV_0_6_MHZ>;
			status = "disabled";
		};
		/* Not in the default walk. Set status okay to verify this scaled frequency. */
		pstate_mx_he_hfxo384_x29: pstate_mx_he_hfxo384_x29 {
			compatible = "alif,rtss-pstate";
			load-threshold = <0>;
			cpu-clk-freq = <ALIF_CLOCK_FREQ_38_4_XO_MHZ>;
			clk-src = "hfxo";
			scaled-clk-freq = <ALIF_SCALED_FREQ_XO_HIGH_DIV_0_3_MHZ>;
			status = "disabled";
		};
		/* Not in the default walk. Set status okay to verify this scaled frequency. */
		pstate_mx_he_hfxo384_x30: pstate_mx_he_hfxo384_x30 {
			compatible = "alif,rtss-pstate";
			load-threshold = <0>;
			cpu-clk-freq = <ALIF_CLOCK_FREQ_38_4_XO_MHZ>;
			clk-src = "hfxo";
			scaled-clk-freq = <ALIF_SCALED_FREQ_XO_HIGH_DIV_0_15_MHZ>;
			status = "disabled";
		};
		/* Not in the default walk. Set status okay to verify this scaled frequency. */
		pstate_mx_he_hfxo384_x31: pstate_mx_he_hfxo384_x31 {
			compatible = "alif,rtss-pstate";
			load-threshold = <0>;
			cpu-clk-freq = <ALIF_CLOCK_FREQ_38_4_XO_MHZ>;
			clk-src = "hfxo";
			scaled-clk-freq = <ALIF_SCALED_FREQ_XO_HIGH_DIV_0_0375_MHZ>;
			status = "disabled";
		};
	};
};
